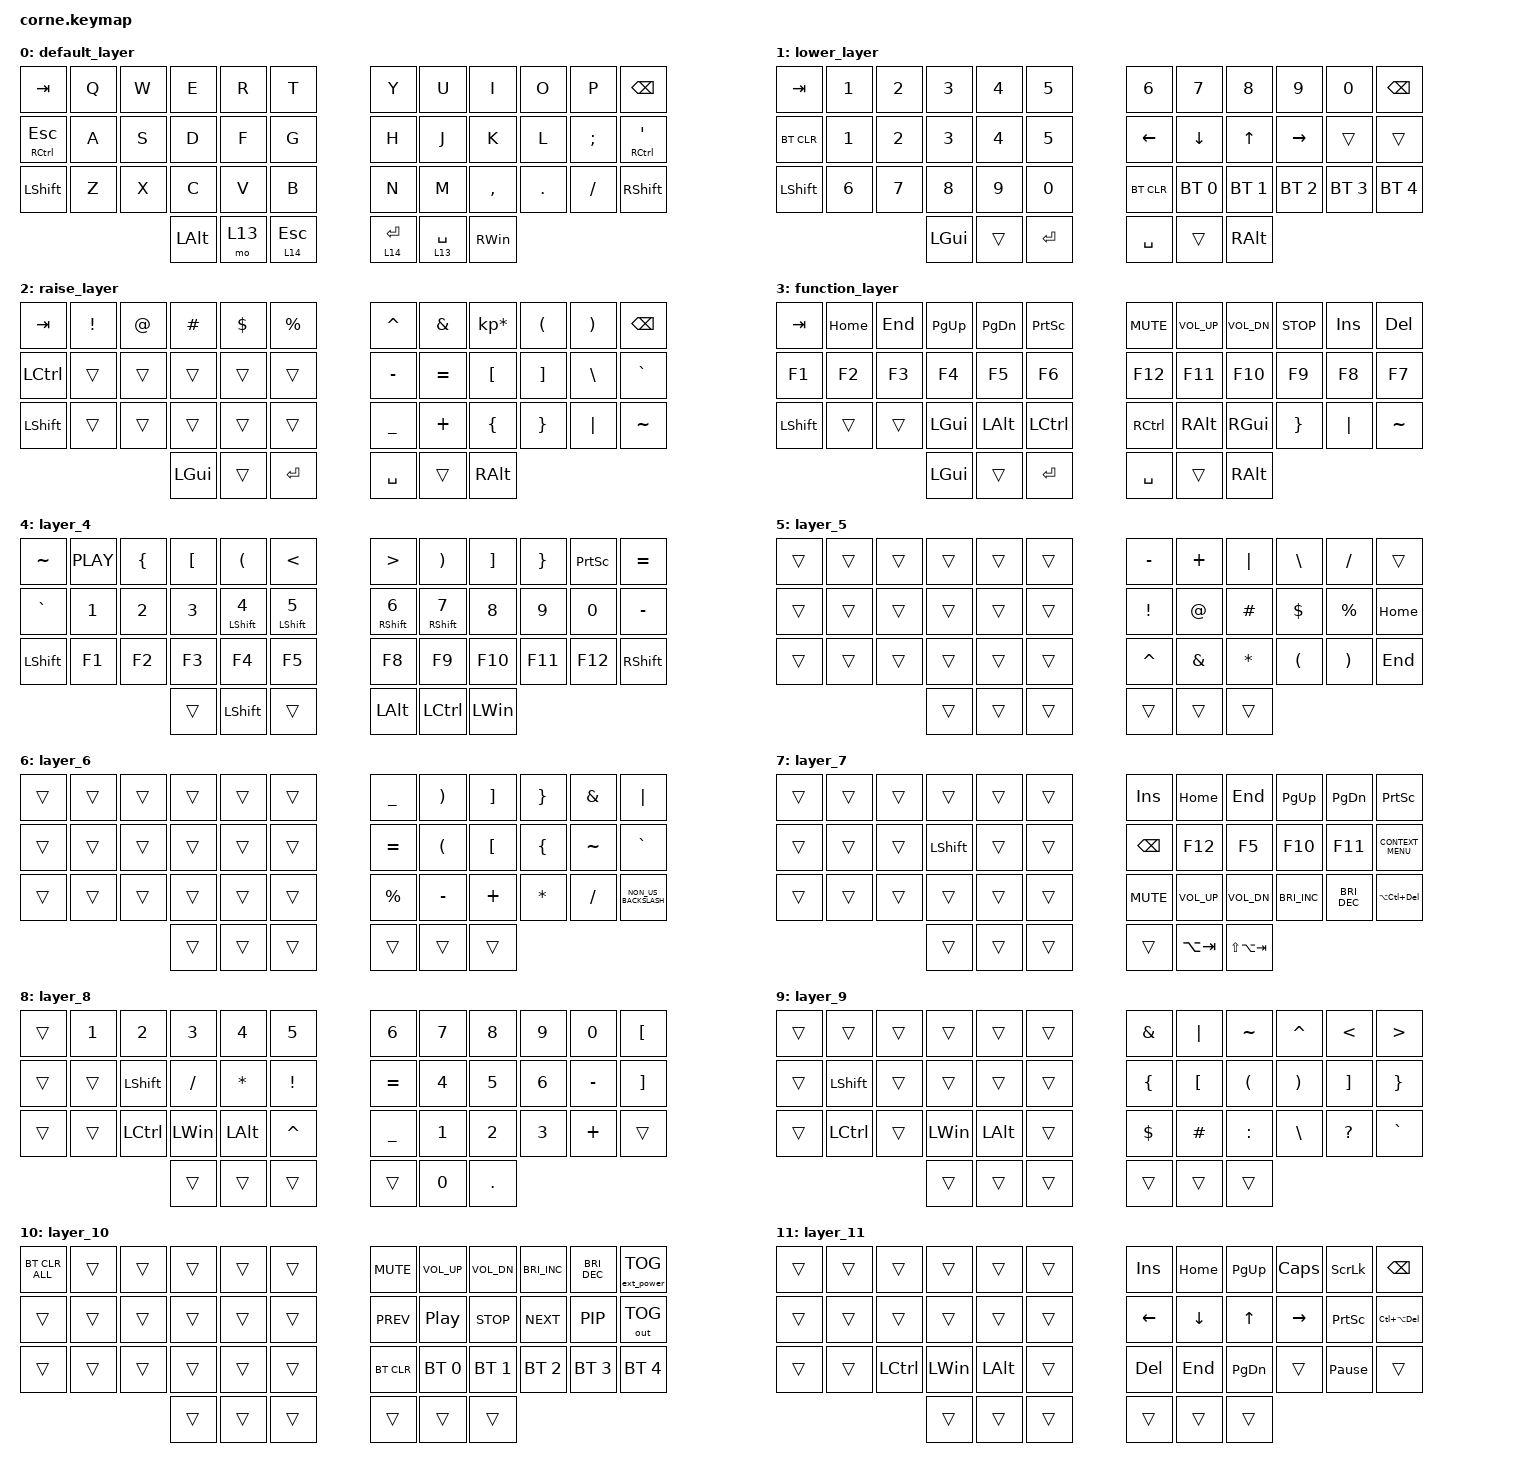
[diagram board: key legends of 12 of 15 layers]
/*
 * Copyright (c) 2020 The ZMK Contributors
 *
 * SPDX-License-Identifier: MIT
 */

#include <behaviors.dtsi>
#include <dt-bindings/zmk/bt.h>
#include <dt-bindings/zmk/ext_power.h>
#include <dt-bindings/zmk/keys.h>
#include <dt-bindings/zmk/outputs.h>

// #include <dt-bindings/zmk/ext_power.h>
// #include <dt-bindings/zmk/output.h>
// &mt {
//     tapping-term-ms = <400>;
// };
// &caps_word {
//    continue-list = <UNDERSCORE MINUS BACKSPACE>;
// };
// Macros

#define AS(keycode) &as LS(keycode) keycode     // Autoshift Macro

// To do
// - find a place for FUNC, MEDIA, and MOUSE to be toggled, maybe both thumbs toggles a selection layer?
// Backspace/delete multiple on double tap hold

&lt {
    tapping-term-ms = <250>;
    quick_tap_ms = <200>;
    flavor = "tap-preferred";
};

/ {
    behaviors {
        as: auto_shift {
            compatible = "zmk,behavior-hold-tap";
            label = "AUTO_SHIFT";
            #binding-cells = <2>;
            tapping_term_ms = <200>;
            quick_tap_ms = <0>;
            flavor = "tap-preferred";
            bindings = <&kp>, <&kp>;
        };

        hm: homerow {
            compatible = "zmk,behavior-hold-tap";
            label = "HOMEROW_MODS";
            #binding-cells = <2>;
            tapping-term-ms = <300>;// <---[[moderate duration]]
            quick-tap-ms = <0>;
            flavor = "tap-preferred";
            bindings = <&kp>, <&kp>;
        };

        hshft: homerow_shift {
            compatible = "zmk,behavior-hold-tap";
            label = "HOMEROW_MODS_SHIFT";
            #binding-cells = <2>;
            tapping-term-ms = <200>;
            quick-tap-ms = <199>;
            flavor = "tap-preferred";
            bindings = <&kp>, <&kp>;
        };

        ht_tp: holdtap_tappreferred {
            compatible = "zmk,behavior-hold-tap";
            label = "HOLD_TAP_TAP_PREFERRED";
            #binding-cells = <2>;
            flavor = "balanced";
            tapping-term-ms = <400>;
            quick-tap-ms = <0>;
            bindings = <&kp>, <&kp>;
        };

        skq: sticky_key_quick_release {
            compatible = "zmk,behavior-sticky-key";
            label = "STICKY_KEY_QUICK_RELEASE";
            #binding-cells = <1>;
            bindings = <&kp>;
            release-after-ms = <1000>;
            quick-release;
        };

        hltr: hold_layer_tap_repeat {
            label = "HOLD_LAYER_TAP_REPEAT";
            #binding-cells = <2>;
            compatible = "zmk,behavior-hold-tap";
            bindings = <&mo>, <&key_repeat>;

            tapping-term-ms = <120>;
            flavor = "tap-preferred";
        };

        hmtsk: hold_mod_tap_sticky_key {
            label = "HOLD_MOD_TAP_STICKY_KEY";
            #binding-cells = <2>;
            compatible = "zmk,behavior-hold-tap";
            bindings = <&kp>, <&skq>;

            tapping-term-ms = <120>;
            flavor = "tap-preferred";
        };

        hltsk: hold_layer_tap_sticky_key {
            label = "HOLD_LAYER_TAP_STICKY_KEY";
            #binding-cells = <2>;
            compatible = "zmk,behavior-hold-tap";
            bindings = <&mo>, <&skq>;

            tapping-term-ms = <120>;
            flavor = "tap-preferred";
        };

        hltsl: hold_layer_tap_sticky_layer {
            label = "HOLD_LAYER_TAP_STICKY_LAYER";
            #binding-cells = <2>;
            compatible = "zmk,behavior-hold-tap";
            bindings = <&mo>, <&sl>;

            tapping-term-ms = <120>;
            flavor = "tap-preferred";
        };
    };

    combos {
        compatible = "zmk,combos";

        combo_commadot_tab {
            layers = <0 1 2>;
            timeout-ms = <50>;

            // , + . = shift

            key-positions = <15 16>;
            bindings = <&kp TAB>;
        };

        combo_commadot_ret {
            layers = <0 1 2>;
            timeout-ms = <50>;

            // , + . = shift

            key-positions = <19 20>;
            bindings = <&kp RET>;
        };

        combo_backspace {
            bindings = <&kp BACKSPACE>;
            key-positions = <20 21>;
        };

        Alt+Tab {
            bindings = <&kp LA(TAB)>;
            key-positions = <14 15 16>;
        };
    };
};

/ {
    keymap {
        compatible = "zmk,keymap";

        default_layer {
            // -----------------------------------------------------------------------------------------
            // |  TAB |  Q  |  W  |  E  |  R  |  T  |   |  Y  |  U   |  I  |  O  |  P  | BKSP |
            // | CTRL |  A  |  S  |  D  |  F  |  G  |   |  H  |  J   |  K  |  L  |  ;  |  '   |
            // | SHFT |  Z  |  X  |  C  |  V  |  B  |   |  N  |  M   |  ,  |  .  |  /  | ESC  |
            //                    | GUI | LWR | ENT |   | SPC | RSE  | ALT |

            bindings = <
&kp TAB                   &kp Q  &kp W  &kp E         &kp R   &kp T            &kp Y         &kp U         &kp I          &kp O       &kp P          &kp BACKSPACE
&ht_tp RIGHT_CONTROL ESC  &kp A  &kp S  &kp D         &kp F   &kp G            &kp H         &kp J         &kp K          &kp L       &kp SEMICOLON  &ht_tp RCTRL SQT
&kp LSHFT                 &kp Z  &kp X  &kp C         &kp V   &kp B            &kp N         &kp M         &kp COMMA      &kp PERIOD  &kp SLASH      &kp RSHFT
                                        &kp LEFT_ALT  &mo 13  &lt 14 ESCAPE    &lt 14 ENTER  &lt 13 SPACE  &kp RIGHT_WIN
            >;
        };

        lower_layer {
            // -----------------------------------------------------------------------------------------
            // |  TAB |  1  |  2  |  3  |  4  |  5  |   |  6  |  7  |  8  |  9  |  0  | BKSP |
            // | BTCLR| BT1 | BT2 | BT3 | BT4 | BT5 |   | LFT | DWN |  UP | RGT |     |      |
            // | SHFT |     |     |     |     |     |   |     |     |     |     |     |      |
            //                    | GUI |     | ENT |   | SPC |     | ALT |

            bindings = <
&kp TAB     &kp N1  &kp N2  &kp N3    &kp N4  &kp N5     &kp N6      &kp N7        &kp N8        &kp N9        &kp N0        &kp BSPC
&bt BT_CLR  &kp N1  &kp N2  &kp N3    &kp N4  &kp N5     &kp LEFT    &kp DOWN      &kp UP        &kp RIGHT     &trans        &trans
&kp LSHFT   &kp N6  &kp N7  &kp N8    &kp N9  &kp N0     &bt BT_CLR  &bt BT_SEL 0  &bt BT_SEL 1  &bt BT_SEL 2  &bt BT_SEL 3  &bt BT_SEL 4
                            &kp LGUI  &trans  &kp RET    &kp SPACE   &trans        &kp RALT
            >;
        };

        raise_layer {
            // -----------------------------------------------------------------------------------------
            // |  TAB |  !  |  @  |  #  |  $  |  %  |   |  ^  |  &  |  *  |  (  |  )  | BKSP |
            // | CTRL |     |     |     |     |     |   |  -  |  =  |  [  |  ]  |  \  |  `   |
            // | SHFT |     |     |     |     |     |   |  _  |  +  |  {  |  }  | "|" |  ~   |
            //                    | GUI |     | ENT |   | SPC |     | ALT |

            bindings = <
&kp TAB    &kp EXCL  &kp AT  &kp HASH  &kp DLLR  &kp PRCNT    &kp CARET  &kp AMPS   &kp KP_MULTIPLY  &kp LPAR  &kp RPAR  &kp BSPC
&kp LCTRL  &trans    &trans  &trans    &trans    &trans       &kp MINUS  &kp EQUAL  &kp LBKT         &kp RBKT  &kp BSLH  &kp GRAVE
&kp LSHFT  &trans    &trans  &trans    &trans    &trans       &kp UNDER  &kp PLUS   &kp LBRC         &kp RBRC  &kp PIPE  &kp TILDE
                             &kp LGUI  &trans    &kp RET      &kp SPACE  &trans     &kp RALT
            >;
        };

        function_layer {
            // -----------------------------------------------------------------------------------------
            // |  TAB |  !  |  @  |  #  |  $  |  %  |   |  ^  |  &  |  *  |  (  |  )  | BKSP |
            // | CTRL |     |     |     |     |     |   |  -  |  =  |  [  |  ]  |  \  |  `   |
            // | SHFT |     |     |     |     |     |   |  _  |  +  |  {  |  }  | "|" |  ~   |
            //                    | GUI |     | ENT |   | SPC |     | ALT |

            bindings = <
&kp TAB    &kp HOME  &kp END  &kp PG_UP  &kp PG_DN  &kp PSCRN    &kp C_MUTE  &kp C_VOL_UP  &kp C_VOL_DN  &kp C_STOP  &kp INS   &kp DEL
&kp F1     &kp F2    &kp F3   &kp F4     &kp F5     &kp F6       &kp F12     &kp F11       &kp F10       &kp F9      &kp F8    &kp F7
&kp LSHFT  &trans    &trans   &kp LGUI   &kp LALT   &kp LCTRL    &kp RCTRL   &kp RALT      &kp RGUI      &kp RBRC    &kp PIPE  &kp TILDE
                              &kp LGUI   &trans     &kp RET      &kp SPACE   &trans        &kp RALT
            >;
        };

        layer_4 {
            bindings = <
&kp TILDE       &kp C_PLAY    &kp LEFT_BRACE  &kp LEFT_BRACKET  &kp LEFT_PARENTHESIS     &kp LESS_THAN        &kp GREATER_THAN          &kp RIGHT_PARENTHESIS  &kp RIGHT_BRACKET  &kp RIGHT_BRACE  &kp PRINTSCREEN  &kp EQUAL
&kp GRAVE       &kp NUMBER_1  &kp NUMBER_2    &kp NUMBER_3      &mt LEFT_SHIFT NUMBER_4  &mt LEFT_SHIFT N5    &mt RIGHT_SHIFT NUMBER_6  &mt RIGHT_SHIFT N7     &kp NUMBER_8       &kp NUMBER_9     &kp NUMBER_0     &kp MINUS
&kp LEFT_SHIFT  &kp F1        &kp F2          &kp F3            &kp F4                   &kp F5               &kp F8                    &kp F9                 &kp F10            &kp F11          &kp F12          &kp RIGHT_SHIFT
                                              &trans            &kp LEFT_SHIFT           &trans               &kp LEFT_ALT              &kp LEFT_CONTROL       &kp LEFT_WIN
            >;
        };

        layer_5 {
            bindings = <
&trans  &trans  &trans  &trans  &trans  &trans    &kp MINUS        &kp PLUS       &kp PIPE      &kp BACKSLASH         &kp SLASH              &trans
&trans  &trans  &trans  &trans  &trans  &trans    &kp EXCLAMATION  &kp AT_SIGN    &kp HASH      &kp DOLLAR            &kp PERCENT            &kp HOME
&trans  &trans  &trans  &trans  &trans  &trans    &kp CARET        &kp AMPERSAND  &kp ASTERISK  &kp LEFT_PARENTHESIS  &kp RIGHT_PARENTHESIS  &kp END
                        &trans  &trans  &trans    &trans           &trans         &trans
            >;
        };

        layer_6 {
            bindings = <
&trans  &trans  &trans  &trans  &trans  &trans    &kp UNDERSCORE  &kp RIGHT_PARENTHESIS  &kp RIGHT_BRACKET  &kp RIGHT_BRACE  &kp AMPERSAND  &kp PIPE
&trans  &trans  &trans  &trans  &trans  &trans    &kp EQUAL       &kp LEFT_PARENTHESIS   &kp LEFT_BRACKET   &kp LEFT_BRACE   &kp TILDE      &kp GRAVE
&trans  &trans  &trans  &trans  &trans  &trans    &kp PERCENT     &kp MINUS              &kp PLUS           &kp ASTERISK     &kp SLASH      &kp NON_US_BACKSLASH
                        &trans  &trans  &trans    &trans          &trans                 &trans
            >;
        };

        layer_7 {
            bindings = <
&trans  &trans  &trans  &trans          &trans  &trans    &kp INS        &kp HOME         &kp END          &kp PG_UP             &kp PG_DN             &kp PRINTSCREEN
&trans  &trans  &trans  &kp LEFT_SHIFT  &trans  &trans    &kp BACKSPACE  &kp F12          &kp F5           &kp F10               &kp F11               &kp K_CONTEXT_MENU
&trans  &trans  &trans  &trans          &trans  &trans    &kp C_MUTE     &kp C_VOLUME_UP  &kp C_VOL_DN     &kp C_BRIGHTNESS_INC  &kp C_BRIGHTNESS_DEC  &kp LA(LC(DEL))
                        &trans          &trans  &trans    &trans         &kp LA(TAB)      &kp LS(LA(TAB))
            >;
        };

        layer_8 {
            bindings = <
&trans  &kp NUMBER_1  &kp NUMBER_2    &kp NUMBER_3  &kp NUMBER_4  &kp N5             &kp NUMBER_6    &kp N7        &kp N8        &kp N9        &kp N0     &kp LEFT_BRACKET
&trans  &trans        &kp LEFT_SHIFT  &kp SLASH     &kp ASTERISK  &kp EXCLAMATION    &kp EQUAL       &kp NUMBER_4  &kp N5        &kp NUMBER_6  &kp MINUS  &kp RIGHT_BRACKET
&trans  &trans        &kp LCTRL       &kp LEFT_WIN  &kp LEFT_ALT  &kp CARET          &kp UNDERSCORE  &kp NUMBER_1  &kp NUMBER_2  &kp NUMBER_3  &kp PLUS   &trans
                                      &trans        &trans        &trans             &trans          &kp N0        &kp PERIOD
            >;
        };

        layer_9 {
            bindings = <
&trans  &trans          &trans  &trans        &trans        &trans    &kp AMPERSAND   &kp PIPE          &kp TILDE             &kp CARET              &kp LESS_THAN      &kp GREATER_THAN
&trans  &kp LEFT_SHIFT  &trans  &trans        &trans        &trans    &kp LEFT_BRACE  &kp LEFT_BRACKET  &kp LEFT_PARENTHESIS  &kp RIGHT_PARENTHESIS  &kp RIGHT_BRACKET  &kp RIGHT_BRACE
&trans  &kp LCTRL       &trans  &kp LEFT_WIN  &kp LEFT_ALT  &trans    &kp DOLLAR      &kp HASH          &kp COLON             &kp BACKSLASH          &kp QUESTION       &kp GRAVE
                                &trans        &trans        &trans    &trans          &trans            &trans
            >;
        };

        layer_10 {
            bindings = <
&bt BT_CLR_ALL  &trans  &trans  &trans  &trans  &trans    &kp C_MUTE  &kp C_VOLUME_UP   &kp C_VOL_DN  &kp C_BRIGHTNESS_INC  &kp C_BRIGHTNESS_DEC  &ext_power EP_TOG
&trans          &trans  &trans  &trans  &trans  &trans    &kp C_PREV  &kp C_PLAY_PAUSE  &kp C_STOP    &kp C_NEXT            &kp C_PIP             &out OUT_TOG
&trans          &trans  &trans  &trans  &trans  &trans    &bt BT_CLR  &bt BT_SEL 0      &bt BT_SEL 1  &bt BT_SEL 2          &bt BT_SEL 3          &bt BT_SEL 4
                                &trans  &trans  &trans    &trans      &trans            &trans
            >;
        };

        layer_11 {
            bindings = <
&trans  &trans  &trans            &trans        &trans        &trans    &kp INS     &kp HOME        &kp PAGE_UP    &kp CAPS   &kp SCROLLLOCK   &kp BACKSPACE
&trans  &trans  &trans            &trans        &trans        &trans    &kp LEFT    &kp DOWN_ARROW  &kp UP         &kp RIGHT  &kp PRINTSCREEN  &kp LC(LA(DELETE))
&trans  &trans  &kp LEFT_CONTROL  &kp LEFT_WIN  &kp LEFT_ALT  &trans    &kp DELETE  &kp END         &kp PAGE_DOWN  &trans     &kp PAUSE_BREAK  &trans
                                  &trans        &trans        &trans    &trans      &trans          &trans
            >;
        };

        layer_12 {
            bindings = <
&trans          &trans            &trans        &trans        &trans          &trans    &trans    &kp F7            &kp F8        &kp F9  &kp F10  &trans
&trans          &trans            &trans        &trans        &kp LEFT_SHIFT  &trans    &trans    &kp F4            &kp F5        &kp F6  &kp F11  &trans
&kp LEFT_SHIFT  &kp LEFT_CONTROL  &kp LEFT_WIN  &kp LEFT_ALT  &kp LEFT_ALT    &trans    &trans    &kp F1            &kp F2        &kp F3  &kp F12  &trans
                                                &trans        &trans          &trans    &kp LALT  &kp LEFT_CONTROL  &kp LEFT_WIN
            >;
        };

        layer_13 {
            bindings = <
&kp LS(TILDE)  &kp C_MUTE    &kp C_VOL_DN          &kp C_VOL_UP          &kp K_PLAY_PAUSE  &kp F11       &kp INS     &kp HOME  &kp PAGE_UP    &kp LBKT   &kp RBKT  &kp DELETE
&kp LCTRL      &kp DELETE    &kp C_BRIGHTNESS_DEC  &kp C_BRIGHTNESS_INC  &kp ESCAPE        &kp F12       &kp LEFT    &kp DOWN  &kp UP         &kp RIGHT  &kp BSLH  &kp PRINTSCREEN
&kp LSHFT      &bt BT_SEL 0  &bt BT_SEL 1          &bt BT_SEL 2          &bt BT_SEL 3      &bt BT_CLR    &kp K_CALC  &kp END   &kp PAGE_DOWN  &kp F11    &kp F12   &kp RSHFT
                                                   &kp LALT              &trans            &trans        &trans      &trans    &kp RGUI
            >;
        };

        layer_14 {
            bindings = <
&kp GRAVE  &kp LS(EXCL)  &kp LS(AT)  &kp LS(POUND)  &kp LS(DLLR)  &kp LS(PRCNT)    &kp CARET  &kp LS(AMPS)  &kp LS(STAR)  &kp LS(LPAR)  &kp LS(RPAR)  &kp MINUS
&kp LCTRL  &kp N1        &kp N2      &kp N3         &kp N4        &kp N5           &kp N6     &kp N7        &kp N8        &kp N9        &kp N0        &kp EQUAL
&kp LSHFT  &kp F1        &kp F2      &kp F3         &kp F4        &kp F5           &kp F6     &kp F7        &kp F8        &kp F9        &kp F10       &kp RSHFT
                                     &kp LALT       &trans        &trans           &trans     &trans        &kp RGUI
            >;
        };
    };
};
